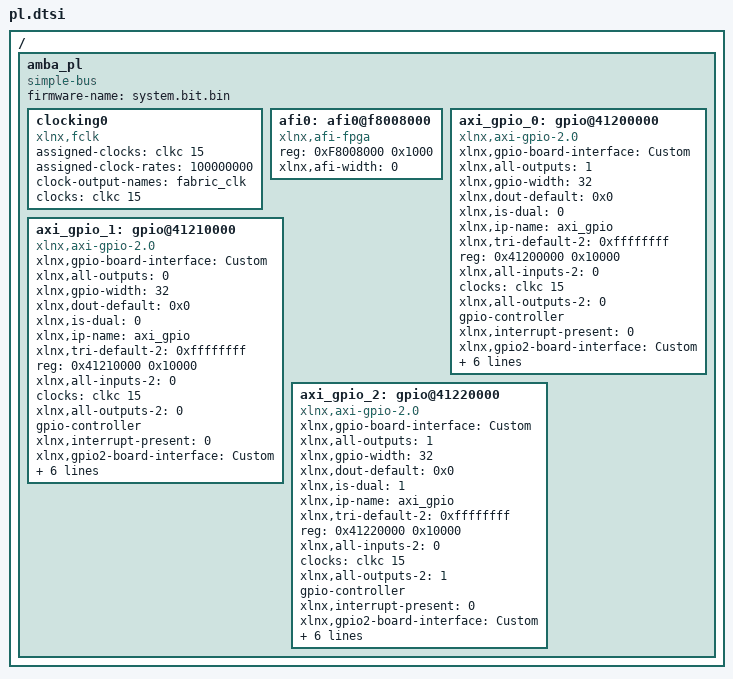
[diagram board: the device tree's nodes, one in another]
/ {
	amba_pl: amba_pl {
		ranges;
		compatible = "simple-bus";
		#address-cells = <1>;
		#size-cells = <1>;
		firmware-name = "system.bit.bin";
		clocking0: clocking0 {
			compatible = "xlnx,fclk";
			assigned-clocks = <&clkc 15>;
			assigned-clock-rates = <100000000>;
			#clock-cells = <0>;
			clock-output-names = "fabric_clk";
			clocks = <&clkc 15>;
		};
		afi0: afi0@f8008000 {
			status = "okay";
			compatible = "xlnx,afi-fpga";
			#address-cells = <1>;
			reg = <0xF8008000 0x1000>;
			#size-cells = <0>;
			xlnx,afi-width = <0>;
		};
		axi_gpio_0: gpio@41200000 {
			xlnx,gpio-board-interface = "Custom";
			compatible = "xlnx,axi-gpio-2.0" , "xlnx,xps-gpio-1.00.a";
			xlnx,all-outputs = <1>;
			#gpio-cells = <2>;
			xlnx,gpio-width = <32>;
			xlnx,dout-default = <0x0>;
			xlnx,is-dual = <0>;
			xlnx,ip-name = "axi_gpio";
			xlnx,tri-default-2 = <0xffffffff>;
			reg = <0x41200000 0x10000>;
			xlnx,all-inputs-2 = <0>;
			clocks = <&clkc 15>;
			xlnx,all-outputs-2 = <0>;
			gpio-controller;
			xlnx,interrupt-present = <0>;
			xlnx,gpio2-board-interface = "Custom";
			xlnx,edk-iptype = "PERIPHERAL";
			xlnx,dout-default-2 = <0x0>;
			status = "okay";
			xlnx,gpio2-width = <32>;
			clock-names = "s_axi_aclk";
			xlnx,tri-default = <0xffffffff>;
			xlnx,name = "axi_gpio_0";
			xlnx,all-inputs = <0>;
		};
		axi_gpio_1: gpio@41210000 {
			xlnx,gpio-board-interface = "Custom";
			compatible = "xlnx,axi-gpio-2.0" , "xlnx,xps-gpio-1.00.a";
			xlnx,all-outputs = <0>;
			#gpio-cells = <2>;
			xlnx,gpio-width = <32>;
			xlnx,dout-default = <0x0>;
			xlnx,is-dual = <0>;
			xlnx,ip-name = "axi_gpio";
			xlnx,tri-default-2 = <0xffffffff>;
			reg = <0x41210000 0x10000>;
			xlnx,all-inputs-2 = <0>;
			clocks = <&clkc 15>;
			xlnx,all-outputs-2 = <0>;
			gpio-controller;
			xlnx,interrupt-present = <0>;
			xlnx,gpio2-board-interface = "Custom";
			xlnx,edk-iptype = "PERIPHERAL";
			xlnx,dout-default-2 = <0x0>;
			status = "okay";
			xlnx,gpio2-width = <32>;
			clock-names = "s_axi_aclk";
			xlnx,tri-default = <0xffffffff>;
			xlnx,name = "axi_gpio_1";
			xlnx,all-inputs = <1>;
		};
		axi_gpio_2: gpio@41220000 {
			xlnx,gpio-board-interface = "Custom";
			compatible = "xlnx,axi-gpio-2.0" , "xlnx,xps-gpio-1.00.a";
			xlnx,all-outputs = <1>;
			#gpio-cells = <2>;
			xlnx,gpio-width = <32>;
			xlnx,dout-default = <0x0>;
			xlnx,is-dual = <1>;
			xlnx,ip-name = "axi_gpio";
			xlnx,tri-default-2 = <0xffffffff>;
			reg = <0x41220000 0x10000>;
			xlnx,all-inputs-2 = <0>;
			clocks = <&clkc 15>;
			xlnx,all-outputs-2 = <1>;
			gpio-controller;
			xlnx,interrupt-present = <0>;
			xlnx,gpio2-board-interface = "Custom";
			xlnx,edk-iptype = "PERIPHERAL";
			xlnx,dout-default-2 = <0x0>;
			status = "okay";
			xlnx,gpio2-width = <32>;
			clock-names = "s_axi_aclk";
			xlnx,tri-default = <0xffffffff>;
			xlnx,name = "axi_gpio_2";
			xlnx,all-inputs = <0>;
		};
	};
};
